# MSS_DEBUGSS register map
Vendor: Texas Instruments
Registers are 32-bit, read-write, no defined reset value unless marked. A register's access mark holds for its fields unless they carry their own. Offsets are as the file gives them; [hi:lo] are bit positions; {n}, {i} and the like mark numbered series; 'fields as' and 'values as' point back to an identical list.

## MSS_DEBUGSS (part 2 of 2)
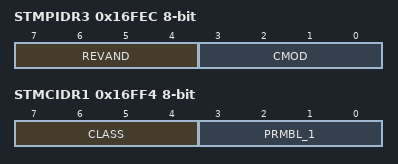
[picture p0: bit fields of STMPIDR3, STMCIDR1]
0x16FEC STMPIDR3 8-bit ro — Peripheral ID3
  [7:4] REVAND — Indicates minor errata fixes specific to the design, for example metal fixes after implementation. In most cases this field is zero. ARM recommends that the component designers ensure that the bit field can be changed by a metal fix if required, for example by driving the bit field from registers that reset to zero. 0x0 No metal fixes in the component.
  [3:0] CMOD — Where the component is reusable IP, this value indicates whether the customer has modified the behavior of the component. In most cases this field is zero. 0x0 No modifications made.
0x16FF0 STMCIDR0 8-bit ro — Component ID0
  [7:0] PRMBL_0 — Contains bits [31:21] of the component identification. 0x0D Identification value.
0x16FF4 STMCIDR1 8-bit ro — Component ID1
  [7:4] CLASS — Class of the component, for example, the ROM table or CoreSight component. 0x9 Indicates the component is a CoreSight component.
  [3:0] PRMBL_1 — Contains bits [19:16] of the component identification. 0x0 Identification value.
0x16FF8 STMCIDR2 8-bit ro — Component ID2
  [7:0] PRMBL_2 — Contains bits [15:8] of the component identification. 0x05 Identification value.
0x16FFC STMCIDR3 8-bit ro — Component ID3
  [7:0] PRMBL_3 — Contains bits [7:0] of the component identification. 0xB1 Identification value.
0x17000 MDO_TPIU_SPORTSZ ro — Supported port sizes
0x17004 MDO_TPIU_CPORTSZ — Current port size
0x17100 MDO_TPIU_STRIGM ro — Supported trigger modes
0x17104 MDO_TPIU_TRIGCNT — Trigger counter value
0x17108 MDO_TPIU_TRIGMUL — Trigger multiplier
0x17200 MDO_TPIU_STSTPTRN ro — Supported test pattern/modes
0x17204 MDO_TPIU_CTSTPTRN — Current test pattern/mode
0x17208 MDO_TPIU_TPRCNTR — Test pattern repeat counter
0x17300 MDO_TPIU_FFSTS ro — Formatter and flush status
0x17304 MDO_TPIU_FFCTRL — Formatter and flush control
0x17308 MDO_TPIU_FSCNTR — Formatter synchronization counter
0x17400 MDO_TPIU_EXCTLIN ro — EXTCTL In Port
0x17404 MDO_TPIU_EXCTLOUT — EXTCTL Out Port
0x17EE4 MDO_TPIU_ITTRFLINACK wo — Integration Register, ITTRFLINACK
0x17EE8 MDO_TPIU_ITTRFLIN ro — Integration Register, ITTRFLIN
0x17EEC MDO_TPIU_ITATBDATA0 ro — Integration Register, ITATBDATA0
0x17EF0 MDO_TPIU_ITATBCTR2 wo — Integration Register, ITATBCTR2
0x17EF4 MDO_TPIU_ITATBCTR1 ro — Integration Register, ITATBCTR1
0x17EF8 MDO_TPIU_ITATBCTR0 ro — Integration Register, ITATBCTR0
0x17F00 MDO_TPIU_ITCTRL — Integration Mode Control Register
0x17FA0 MDO_TPIU_CLAIMSET — Claim Tag Set
0x17FA4 MDO_TPIU_CLAIMCLR — Claim Tag Clear
0x17FB0 MDO_TPIU_LAR ro — Lock status
0x17FB4 MDO_TPIU_LSR wo — Lock Access
0x17FB8 MDO_TPIU_AUTHSTATUS ro — Authentication status
0x17FC8 MDO_TPIU_DEVID ro — Device ID
0x17FCC MDO_TPIU_DEVTYPE ro — Device type identifier
{0x17FC0+4i} MDO_TPIU_PIDR{i} ro (i=4..7) — Peripheral ID{i}
{0x17FE0+4i} MDO_TPIU_PIDR{i} ro (i=0..3) — Peripheral ID{i}
{0x17FF0+4i} MDO_TPIU_CIDR{i} ro (i=0..3) — Component ID{i}
0x18000 HSM_CM4_CTI_CONTROL — http://infocenter.arm.com/help/topic/com.arm.doc.ddi0314h/Chdjefbi.html http://infocenter.arm.com/help/topic/com.arm.doc.ddi0314h/Chdefejc.html
  [31:0] HSM_CM4_CTI_CONTROL — http://infocenter.arm.com/help/topic/com.arm.doc.ddi0480e/CHDGDIHE.html http://infocenter.arm.com/help/topic/com.arm.doc.ddi0480e/CHDHBDIA.html
0x18010 HSM_CM4_CTI_INTACK wo
0x18014 HSM_CM4_CTI_APPSET
0x18018 HSM_CM4_CTI_APPCLEAR wo
0x1801C HSM_CM4_CTI_APPPULSE wo
{0x18020+4i} HSM_CM4_CTI_INEN{i} (i=0..7)
{0x180A0+4i} HSM_CM4_CTI_OUTEN{i} (i=0..7)
0x18130 HSM_CM4_CTI_TRIGINSTATUS ro
0x18134 HSM_CM4_CTI_TRIGOUTSTATUS ro
0x18138 HSM_CM4_CTI_CHINSTATUS ro
0x1813C HSM_CM4_CTI_CHOUTSTATUS ro
0x18140 HSM_CM4_CTI_GATE
0x18144 HSM_CM4_CTI_ASICCTL
0x18EDC HSM_CM4_CTI_ITCHINACK wo
0x18EE0 HSM_CM4_CTI_ITTRIGINACK wo
0x18EE4 HSM_CM4_CTI_ITCHOUT wo
0x18EE8 HSM_CM4_CTI_ITTRIGOUT wo
0x18EEC HSM_CM4_CTI_ITCHOUTACK ro
0x18EF0 HSM_CM4_CTI_ITTRIGOUTACK ro
0x18EF4 HSM_CM4_CTI_ITCHIN ro
0x18EF8 HSM_CM4_CTI_ITTRIGIN ro
0x18F00 HSM_CM4_CTI_ITCTRL
0x18FA0 HSM_CM4_CTI_Claim_Tag_Set
0x18FA4 HSM_CM4_CTI_Claim_Tag_Clear
0x18FB0 HSM_CM4_CTI_Lock_Access_Register wo
0x18FB4 HSM_CM4_CTI_Lock_Status_Register ro
0x18FB8 HSM_CM4_CTI_Authentication_Status ro
0x18FC8 HSM_CM4_CTI_Device_ID ro
0x18FCC HSM_CM4_CTI_Device_Type_Identifier ro
{0x18FC0+4i} HSM_CM4_CTI_PeripheralID{i} ro (i=4..7)
{0x18FE0+4i} HSM_CM4_CTI_PeripheralID{i} ro (i=0..3)
{0x18FF0+4i} HSM_CM4_CTI_Component_ID{i} ro (i=0..3)
0x19000 DSS_CM4_CTI_CONTROL — http://infocenter.arm.com/help/topic/com.arm.doc.ddi0314h/Chdjefbi.html http://infocenter.arm.com/help/topic/com.arm.doc.ddi0314h/Chdefejc.html
0x19010 DSS_CM4_CTI_INTACK wo
0x19014 DSS_CM4_CTI_APPSET
0x19018 DSS_CM4_CTI_APPCLEAR wo
0x1901C DSS_CM4_CTI_APPPULSE wo
{0x19020+4i} DSS_CM4_CTI_INEN{i} (i=0..7)
{0x190A0+4i} DSS_CM4_CTI_OUTEN{i} (i=0..7)
0x19130 DSS_CM4_CTI_TRIGINSTATUS ro
0x19134 DSS_CM4_CTI_TRIGOUTSTATUS ro
0x19138 DSS_CM4_CTI_CHINSTATUS ro
0x1913C DSS_CM4_CTI_CHOUTSTATUS ro
0x19140 DSS_CM4_CTI_GATE
0x19144 DSS_CM4_CTI_ASICCTL
0x19EDC DSS_CM4_CTI_ITCHINACK wo
0x19EE0 DSS_CM4_CTI_ITTRIGINACK wo
0x19EE4 DSS_CM4_CTI_ITCHOUT wo
0x19EE8 DSS_CM4_CTI_ITTRIGOUT wo
0x19EEC DSS_CM4_CTI_ITCHOUTACK ro
0x19EF0 DSS_CM4_CTI_ITTRIGOUTACK ro
0x19EF4 DSS_CM4_CTI_ITCHIN ro
0x19EF8 DSS_CM4_CTI_ITTRIGIN ro
0x19F00 DSS_CM4_CTI_ITCTRL
0x19FA0 DSS_CM4_CTI_Claim_Tag_Set
0x19FA4 DSS_CM4_CTI_Claim_Tag_Clear
0x19FB0 DSS_CM4_CTI_Lock_Access_Register wo
0x19FB4 DSS_CM4_CTI_Lock_Status_Register ro
0x19FB8 DSS_CM4_CTI_Authentication_Status ro
0x19FC8 DSS_CM4_CTI_Device_ID ro
0x19FCC DSS_CM4_CTI_Device_Type_Identifier ro
{0x19FC0+4i} DSS_CM4_CTI_PeripheralID{i} ro (i=4..7)
{0x19FE0+4i} DSS_CM4_CTI_PeripheralID{i} ro (i=0..3)
{0x19FF0+4i} DSS_CM4_CTI_Component_ID{i} ro (i=0..3)
0x1A000 RSS_APB_DBGDIDR — Debug Identification Register
  [31:0] RSS_APB_DBGDIDR — http://infocenter.arm.com/help/topic/com.arm.doc.ddi0363e/Cegejeeb.html Debug Identification Register
0x1A018 RSS_APB_DBGWFAR — Watchpoint Fault Address Register
0x1A01C RSS_APB_DBGVCR — Vector Catch Register
0x1A024 RSS_APB_DBGECR — Not Implemented
0x1A028 RSS_APB_DBGDSCCR — Debug State Cache Control Register
0x1A080 RSS_APB_DBGDTRRX — Host to Target Data Transfer Register
0x1A084 RSS_APB_DBGITR — Instruction Transfer Register
0x1A088 RSS_APB_DBGDSCR — Debug Status and Control Register
0x1A08C RSS_APB_DBGDTRTX — Target to Host Data Transfer Register
0x1A090 RSS_APB_DBGDRCR — Debug Run Control Register
{0x1A100+4i} RSS_APB_DBGBVR{i} (i=0..7) — Break Point Value Register {i}
{0x1A140+4i} RSS_APB_DBGBCR{i} (i=0..7) — Break Point Control Register {i}
{0x1A180+4i} RSS_APB_DBGWVR{i} (i=0..7) — Watch Point Value Register {i}
{0x1A1C0+4i} RSS_APB_DBGWCR{i} (i=0..7) — Watch Point Control Register {i}
0x1A300 RSS_APB_DBGOSLAR — Not Implemented
0x1A304 RSS_APB_DBGOSLSR — Operating System Lock Status Register
0x1A308 RSS_APB_DBGOSSRR — Not Implemented
0x1A310 RSS_APB_DBGPRCR — Device Power Down and Reset Control Regsiter
0x1A314 RSS_APB_DBGPRSR — Device Power Down and Reset Status Register
0x1AD00 RSS_APB_PROCID_MIDR — Main ID Register
0x1AD04 RSS_APB_PROCID_CTR — Cache Type Register
0x1AD08 RSS_APB_PROCID_TCMTR — TCM Type Register
0x1AD10 RSS_APB_PROCID_MPUIR — MPU Type Register
0x1AD14 RSS_APB_PROCID_MPIDR — Multiprocessor Affinity Register
0x1AD20 RSS_APB_PROCID_PFR0 — Processor Feature Register 0
0x1AD24 RSS_APB_PROCID_PFR1 — Processor Feature Register 1
0x1AD28 RSS_APB_PROCID_DFR0 — Debug Feature Register 0
0x1AD2C RSS_APB_PROCID_AFR0 — Auxiliary Feature Register 0
0x1AD30 RSS_APB_PROCID_MMFR0 — Processor Feature Register 0
{0x1AD30+4i} RSS_APB_PROCID_MMFR{i} (i=1..3) — Memory Model Feature Register {i}
{0x1AD40+4i} RSS_APB_PROCID_ISAR{i} (i=0..5) — ISA Feature Register {i}
0x1AF00 RSS_APB_MR_ITCTRL — Integration Mode Control Registers
0x1AFA0 RSS_APB_MR_CLAIMSET — Claim Tag Set Register
0x1AFA4 RSS_APB_MR_CLAIMCLR — Claim Tag Clear Register
0x1AFB0 RSS_APB_MR_LOCKACCESS — Lock Access Register
0x1AFB4 RSS_APB_MR_LOCKSTATUS — Lock Status Register
0x1AFB8 RSS_APB_MR_AUTHSTATUS — Authentication Status Register
0x1AFC8 RSS_APB_MR_DEVID — Device Identifier
0x1AFCC RSS_APB_MR_DEVTYPE — Device Type Register
0x1AFD0 RSS_APB_PERIP_ID4
{0x1AFE0+4i} RSS_APB_PERIP_ID{i} (i=0..3)
{0x1AFF0+4i} RSS_APB_COMP_ID{i} (i=0..3)
0x30000 MSS_A_APB_DBGDIDR — Debug Identification Register
  [31:0] MSS_APB_DBGDIDR — http://infocenter.arm.com/help/topic/com.arm.doc.ddi0363e/Cegejeeb.html Debug Identification Register
0x30018 MSS_A_APB_DBGWFAR — Watchpoint Fault Address Register
  [31:0] MSS_APB_DBGWFAR
0x3001C MSS_A_APB_DBGVCR — Vector Catch Register
  [31:0] MSS_APB_DBGVCR
0x30024 MSS_A_APB_DBGECR — Not Implemented
  [31:0] MSS_APB_DBGECR
0x30028 MSS_A_APB_DBGDSCCR — Debug State Cache Control Register
  [31:0] MSS_APB_DBGDSCCR
0x30080 MSS_A_APB_DBGDTRRX — Host to Target Data Transfer Register
  [31:0] MSS_APB_DBGDTRRX
0x30084 MSS_A_APB_DBGITR — Instruction Transfer Register
  [31:0] MSS_APB_DBGITR
0x30088 MSS_A_APB_DBGDSCR — Debug Status and Control Register
  [31:0] MSS_APB_DBGDSCR
0x3008C MSS_A_APB_DBGDTRTX — Target to Host Data Transfer Register
  [31:0] MSS_APB_DBGDTRTX
0x30090 MSS_A_APB_DBGDRCR — Debug Run Control Register
  [31:0] MSS_APB_DBGDRCR
{0x30100+4i} MSS_A_APB_DBGBVR{i} (i=0..7) — Break Point Value Register {i}
  [31:0] MSS_APB_DBGBVR{i}
{0x30140+4i} MSS_A_APB_DBGBCR{i} (i=0..7) — Break Point Control Register {i}
  [31:0] MSS_APB_DBGBCR{i}
{0x30180+4i} MSS_A_APB_DBGWVR{i} (i=0..7) — Watch Point Value Register {i}
  [31:0] MSS_APB_DBGWVR{i}
{0x301C0+4i} MSS_A_APB_DBGWCR{i} (i=0..7) — Watch Point Control Register {i}
  [31:0] MSS_APB_DBGWCR{i}
0x30300 MSS_A_APB_DBGOSLAR — Not Implemented
  [31:0] MSS_APB_DBGOSLAR
0x30304 MSS_A_APB_DBGOSLSR — Operating System Lock Status Register
  [31:0] MSS_APB_DBGOSLSR
0x30308 MSS_A_APB_DBGOSSRR — Not Implemented
  [31:0] MSS_APB_DBGOSSRR
0x30310 MSS_A_APB_DBGPRCR — Device Power Down and Reset Control Regsiter
  [31:0] MSS_APB_DBGPRCR
0x30314 MSS_A_APB_DBGPRSR — Device Power Down and Reset Status Register
  [31:0] MSS_APB_DBGPRSR
0x30D00 MSS_A_APB_PROCID_MIDR — Main ID Register
  [31:0] MSS_APB_PROCID_MIDR
0x30D04 MSS_A_APB_PROCID_CTR — Cache Type Register
  [31:0] MSS_APB_PROCID_CTR
0x30D08 MSS_A_APB_PROCID_TCMTR — TCM Type Register
  [31:0] MSS_APB_PROCID_TCMTR
0x30D10 MSS_A_APB_PROCID_MPUIR — MPU Type Register
  [31:0] MSS_APB_PROCID_MPUIR
0x30D14 MSS_A_APB_PROCID_MPIDR — Multiprocessor Affinity Register
  [31:0] MSS_APB_PROCID_MPIDR
0x30D20 MSS_A_APB_PROCID_PFR0 — Processor Feature Register 0
  [31:0] MSS_APB_PROCID_PFR0
0x30D24 MSS_A_APB_PROCID_PFR1 — Processor Feature Register 1
  [31:0] MSS_APB_PROCID_PFR1
0x30D28 MSS_A_APB_PROCID_DFR0 — Debug Feature Register 0
  [31:0] MSS_APB_PROCID_DFR0
0x30D2C MSS_A_APB_PROCID_AFR0 — Auxiliary Feature Register 0
  [31:0] MSS_APB_PROCID_AFR0
0x30D30 MSS_A_APB_PROCID_MMFR0 — Processor Feature Register 0
  [31:0] MSS_APB_PROCID_MMFR0
{0x30D30+4i} MSS_A_APB_PROCID_MMFR{i} (i=1..3) — Memory Model Feature Register {i}
  [31:0] MSS_APB_PROCID_MMFR{i}
{0x30D40+4i} MSS_A_APB_PROCID_ISAR{i} (i=0..5) — ISA Feature Register {i}
  [31:0] MSS_APB_PROCID_ISAR{i}
0x30F00 MSS_A_APB_MR_ITCTRL — Integration Mode Control Registers
  [31:0] MSS_APB_MR_ITCTRL
0x30FA0 MSS_A_APB_MR_CLAIMSET — Claim Tag Set Register
  [31:0] MSS_APB_MR_CLAIMSET
0x30FA4 MSS_A_APB_MR_CLAIMCLR — Claim Tag Clear Register
  [31:0] MSS_APB_MR_CLAIMCLR
0x30FB0 MSS_A_APB_MR_LOCKACCESS — Lock Access Register
  [31:0] MSS_APB_MR_LOCKACCESS
0x30FB4 MSS_A_APB_MR_LOCKSTATUS — Lock Status Register
  [31:0] MSS_APB_MR_LOCKSTATUS
0x30FB8 MSS_A_APB_MR_AUTHSTATUS — Authentication Status Register
  [31:0] MSS_APB_MR_AUTHSTATUS
0x30FC8 MSS_A_APB_MR_DEVID — Device Identifier
  [31:0] MSS_APB_MR_DEVID
0x30FCC MSS_A_APB_MR_DEVTYPE — Device Type Register
  [31:0] MSS_APB_MR_DEVTYPE
0x30FD0 MSS_A_APB_PERIP_ID4
  [31:0] MSS_APB_PERIP_ID4
{0x30FE0+4i} MSS_A_APB_PERIP_ID{i} (i=0..3)
  [31:0] MSS_APB_PERIP_ID{i}
{0x30FF0+4i} MSS_A_APB_COMP_ID{i} (i=0..3)
  [31:0] MSS_APB_COMP_ID{i}
0x32000 MSS_B_APB_DBGDIDR — Debug Identification Register
  fields as MSS_A_APB_DBGDIDR
0x32018 MSS_B_APB_DBGWFAR — Watchpoint Fault Address Register
  [31:0] MSS_APB_DBGWFAR
0x3201C MSS_B_APB_DBGVCR — Vector Catch Register
  [31:0] MSS_APB_DBGVCR
0x32024 MSS_B_APB_DBGECR — Not Implemented
  [31:0] MSS_APB_DBGECR
0x32028 MSS_B_APB_DBGDSCCR — Debug State Cache Control Register
  [31:0] MSS_APB_DBGDSCCR
0x32080 MSS_B_APB_DBGDTRRX — Host to Target Data Transfer Register
  [31:0] MSS_APB_DBGDTRRX
0x32084 MSS_B_APB_DBGITR — Instruction Transfer Register
  [31:0] MSS_APB_DBGITR
0x32088 MSS_B_APB_DBGDSCR — Debug Status and Control Register
  [31:0] MSS_APB_DBGDSCR
0x3208C MSS_B_APB_DBGDTRTX — Target to Host Data Transfer Register
  [31:0] MSS_APB_DBGDTRTX
0x32090 MSS_B_APB_DBGDRCR — Debug Run Control Register
  [31:0] MSS_APB_DBGDRCR
{0x32100+4i} MSS_B_APB_DBGBVR{i} (i=0..7) — Break Point Value Register {i}
  [31:0] MSS_APB_DBGBVR{i}
{0x32140+4i} MSS_B_APB_DBGBCR{i} (i=0..7) — Break Point Control Register {i}
  [31:0] MSS_APB_DBGBCR{i}
{0x32180+4i} MSS_B_APB_DBGWVR{i} (i=0..7) — Watch Point Value Register {i}
  [31:0] MSS_APB_DBGWVR{i}
{0x321C0+4i} MSS_B_APB_DBGWCR{i} (i=0..7) — Watch Point Control Register {i}
  [31:0] MSS_APB_DBGWCR{i}
0x32300 MSS_B_APB_DBGOSLAR — Not Implemented
  [31:0] MSS_APB_DBGOSLAR
0x32304 MSS_B_APB_DBGOSLSR — Operating System Lock Status Register
  [31:0] MSS_APB_DBGOSLSR
0x32308 MSS_B_APB_DBGOSSRR — Not Implemented
  [31:0] MSS_APB_DBGOSSRR
0x32310 MSS_B_APB_DBGPRCR — Device Power Down and Reset Control Regsiter
  [31:0] MSS_APB_DBGPRCR
0x32314 MSS_B_APB_DBGPRSR — Device Power Down and Reset Status Register
  [31:0] MSS_APB_DBGPRSR
0x32D00 MSS_B_APB_PROCID_MIDR — Main ID Register
  [31:0] MSS_APB_PROCID_MIDR
0x32D04 MSS_B_APB_PROCID_CTR — Cache Type Register
  [31:0] MSS_APB_PROCID_CTR
0x32D08 MSS_B_APB_PROCID_TCMTR — TCM Type Register
  [31:0] MSS_APB_PROCID_TCMTR
0x32D10 MSS_B_APB_PROCID_MPUIR — MPU Type Register
  [31:0] MSS_APB_PROCID_MPUIR
0x32D14 MSS_B_APB_PROCID_MPIDR — Multiprocessor Affinity Register
  [31:0] MSS_APB_PROCID_MPIDR
0x32D20 MSS_B_APB_PROCID_PFR0 — Processor Feature Register 0
  [31:0] MSS_APB_PROCID_PFR0
0x32D24 MSS_B_APB_PROCID_PFR1 — Processor Feature Register 1
  [31:0] MSS_APB_PROCID_PFR1
0x32D28 MSS_B_APB_PROCID_DFR0 — Debug Feature Register 0
  [31:0] MSS_APB_PROCID_DFR0
0x32D2C MSS_B_APB_PROCID_AFR0 — Auxiliary Feature Register 0
  [31:0] MSS_APB_PROCID_AFR0
0x32D30 MSS_B_APB_PROCID_MMFR0 — Processor Feature Register 0
  [31:0] MSS_APB_PROCID_MMFR0
{0x32D30+4i} MSS_B_APB_PROCID_MMFR{i} (i=1..3) — Memory Model Feature Register {i}
  [31:0] MSS_APB_PROCID_MMFR{i}
{0x32D40+4i} MSS_B_APB_PROCID_ISAR{i} (i=0..5) — ISA Feature Register {i}
  [31:0] MSS_APB_PROCID_ISAR{i}
0x32F00 MSS_B_APB_MR_ITCTRL — Integration Mode Control Registers
  [31:0] MSS_APB_MR_ITCTRL
0x32FA0 MSS_B_APB_MR_CLAIMSET — Claim Tag Set Register
  [31:0] MSS_APB_MR_CLAIMSET
0x32FA4 MSS_B_APB_MR_CLAIMCLR — Claim Tag Clear Register
  [31:0] MSS_APB_MR_CLAIMCLR
0x32FB0 MSS_B_APB_MR_LOCKACCESS — Lock Access Register
  [31:0] MSS_APB_MR_LOCKACCESS
0x32FB4 MSS_B_APB_MR_LOCKSTATUS — Lock Status Register
  [31:0] MSS_APB_MR_LOCKSTATUS
0x32FB8 MSS_B_APB_MR_AUTHSTATUS — Authentication Status Register
  [31:0] MSS_APB_MR_AUTHSTATUS
0x32FC8 MSS_B_APB_MR_DEVID — Device Identifier
  [31:0] MSS_APB_MR_DEVID
0x32FCC MSS_B_APB_MR_DEVTYPE — Device Type Register
  [31:0] MSS_APB_MR_DEVTYPE
0x32FD0 MSS_B_APB_PERIP_ID4
  [31:0] MSS_APB_PERIP_ID4
{0x32FE0+4i} MSS_B_APB_PERIP_ID{i} (i=0..3)
  [31:0] MSS_APB_PERIP_ID{i}
{0x32FF0+4i} MSS_B_APB_COMP_ID{i} (i=0..3)
  [31:0] MSS_APB_COMP_ID{i}
0x38000 MSS_A_CTI_CONTROL — http://infocenter.arm.com/help/topic/com.arm.doc.ddi0314h/Chdjefbi.html http://infocenter.arm.com/help/topic/com.arm.doc.ddi0314h/Chdefejc.html
  [31:0] MSS_CTI_CONTROL — http://infocenter.arm.com/help/topic/com.arm.doc.ddi0480e/CHDGDIHE.html http://infocenter.arm.com/help/topic/com.arm.doc.ddi0480e/CHDHBDIA.html
0x38010 MSS_A_CTI_INTACK wo
  [31:0] MSS_CTI_INTACK
0x38014 MSS_A_CTI_APPSET
  [31:0] MSS_CTI_APPSET
0x38018 MSS_A_CTI_APPCLEAR wo
  [31:0] MSS_CTI_APPCLEAR
0x3801C MSS_A_CTI_APPPULSE wo
  [31:0] MSS_CTI_APPPULSE
{0x38020+4i} MSS_A_CTI_INEN{i} (i=0..7)
  [31:0] MSS_CTI_INEN{i}
{0x380A0+4i} MSS_A_CTI_OUTEN{i} (i=0..7)
  [31:0] MSS_CTI_OUTEN{i}
0x38130 MSS_A_CTI_TRIGINSTATUS ro
  [31:0] MSS_CTI_TRIGINSTATUS
0x38134 MSS_A_CTI_TRIGOUTSTATUS ro
  [31:0] MSS_CTI_TRIGOUTSTATUS
0x38138 MSS_A_CTI_CHINSTATUS ro
  [31:0] MSS_CTI_CHINSTATUS
0x3813C MSS_A_CTI_CHOUTSTATUS ro
  [31:0] MSS_CTI_CHOUTSTATUS
0x38140 MSS_A_CTI_GATE
  [31:0] MSS_CTI_GATE
0x38144 MSS_A_CTI_ASICCTL
  [31:0] MSS_CTI_ASICCTL
0x38EDC MSS_A_CTI_ITCHINACK wo
  [31:0] MSS_CTI_ITCHINACK
0x38EE0 MSS_A_CTI_ITTRIGINACK wo
  [31:0] MSS_CTI_ITTRIGINACK
0x38EE4 MSS_A_CTI_ITCHOUT wo
  [31:0] MSS_CTI_ITCHOUT
0x38EE8 MSS_A_CTI_ITTRIGOUT wo
  [31:0] MSS_CTI_ITTRIGOUT
0x38EEC MSS_A_CTI_ITCHOUTACK ro
  [31:0] MSS_CTI_ITCHOUTACK
0x38EF0 MSS_A_CTI_ITTRIGOUTACK ro
  [31:0] MSS_CTI_ITTRIGOUTACK
0x38EF4 MSS_A_CTI_ITCHIN ro
  [31:0] MSS_CTI_ITCHIN
0x38EF8 MSS_A_CTI_ITTRIGIN ro
  [31:0] MSS_CTI_ITTRIGIN
0x38F00 MSS_A_CTI_ITCTRL
  [31:0] MSS_CTI_ITCTRL
0x38FA0 MSS_A_CTI_Claim_Tag_Set
  [31:0] MSS_CTI_Claim_Tag_Set
0x38FA4 MSS_A_CTI_Claim_Tag_Clear
  [31:0] MSS_CTI_Claim_Tag_Clear
0x38FB0 MSS_A_CTI_Lock_Access_Register wo
  [31:0] MSS_CTI_Lock_Access_Register
0x38FB4 MSS_A_CTI_Lock_Status_Register ro
  [31:0] MSS_CTI_Lock_Status_Register
0x38FB8 MSS_A_CTI_Authentication_Status ro
  [31:0] MSS_CTI_Authentication_Status
0x38FC8 MSS_A_CTI_Device_ID ro
  [31:0] MSS_CTI_Device_ID
0x38FCC MSS_A_CTI_Device_Type_Identifier ro
  [31:0] MSS_CTI_Device_Type_Identifier
{0x38FC0+4i} MSS_A_CTI_PeripheralID{i} ro (i=4..7)
  [31:0] MSS_CTI_PeripheralID{i}
{0x38FE0+4i} MSS_A_CTI_PeripheralID{i} ro (i=0..3)
  [31:0] MSS_CTI_PeripheralID{i}
{0x38FF0+4i} MSS_A_CTI_Component_ID{i} ro (i=0..3)
  [31:0] MSS_CTI_Component_ID{i}
0x39000 MSS_B_CTI_CONTROL — http://infocenter.arm.com/help/topic/com.arm.doc.ddi0314h/Chdjefbi.html http://infocenter.arm.com/help/topic/com.arm.doc.ddi0314h/Chdefejc.html
  fields as MSS_A_CTI_CONTROL
0x39010 MSS_B_CTI_INTACK wo
  [31:0] MSS_CTI_INTACK
0x39014 MSS_B_CTI_APPSET
  [31:0] MSS_CTI_APPSET
0x39018 MSS_B_CTI_APPCLEAR wo
  [31:0] MSS_CTI_APPCLEAR
0x3901C MSS_B_CTI_APPPULSE wo
  [31:0] MSS_CTI_APPPULSE
{0x39020+4i} MSS_B_CTI_INEN{i} (i=0..7)
  [31:0] MSS_CTI_INEN{i}
{0x390A0+4i} MSS_B_CTI_OUTEN{i} (i=0..7)
  [31:0] MSS_CTI_OUTEN{i}
0x39130 MSS_B_CTI_TRIGINSTATUS ro
  [31:0] MSS_CTI_TRIGINSTATUS
0x39134 MSS_B_CTI_TRIGOUTSTATUS ro
  [31:0] MSS_CTI_TRIGOUTSTATUS
0x39138 MSS_B_CTI_CHINSTATUS ro
  [31:0] MSS_CTI_CHINSTATUS
0x3913C MSS_B_CTI_CHOUTSTATUS ro
  [31:0] MSS_CTI_CHOUTSTATUS
0x39140 MSS_B_CTI_GATE
  [31:0] MSS_CTI_GATE
0x39144 MSS_B_CTI_ASICCTL
  [31:0] MSS_CTI_ASICCTL
0x39EDC MSS_B_CTI_ITCHINACK wo
  [31:0] MSS_CTI_ITCHINACK
0x39EE0 MSS_B_CTI_ITTRIGINACK wo
  [31:0] MSS_CTI_ITTRIGINACK
0x39EE4 MSS_B_CTI_ITCHOUT wo
  [31:0] MSS_CTI_ITCHOUT
0x39EE8 MSS_B_CTI_ITTRIGOUT wo
  [31:0] MSS_CTI_ITTRIGOUT
0x39EEC MSS_B_CTI_ITCHOUTACK ro
  [31:0] MSS_CTI_ITCHOUTACK
0x39EF0 MSS_B_CTI_ITTRIGOUTACK ro
  [31:0] MSS_CTI_ITTRIGOUTACK
0x39EF4 MSS_B_CTI_ITCHIN ro
  [31:0] MSS_CTI_ITCHIN
0x39EF8 MSS_B_CTI_ITTRIGIN ro
  [31:0] MSS_CTI_ITTRIGIN
0x39F00 MSS_B_CTI_ITCTRL
  [31:0] MSS_CTI_ITCTRL
0x39FA0 MSS_B_CTI_Claim_Tag_Set
  [31:0] MSS_CTI_Claim_Tag_Set
0x39FA4 MSS_B_CTI_Claim_Tag_Clear
  [31:0] MSS_CTI_Claim_Tag_Clear
0x39FB0 MSS_B_CTI_Lock_Access_Register wo
  [31:0] MSS_CTI_Lock_Access_Register
0x39FB4 MSS_B_CTI_Lock_Status_Register ro
  [31:0] MSS_CTI_Lock_Status_Register
0x39FB8 MSS_B_CTI_Authentication_Status ro
  [31:0] MSS_CTI_Authentication_Status
0x39FC8 MSS_B_CTI_Device_ID ro
  [31:0] MSS_CTI_Device_ID
0x39FCC MSS_B_CTI_Device_Type_Identifier ro
  [31:0] MSS_CTI_Device_Type_Identifier
{0x39FC0+4i} MSS_B_CTI_PeripheralID{i} ro (i=4..7)
  [31:0] MSS_CTI_PeripheralID{i}
{0x39FE0+4i} MSS_B_CTI_PeripheralID{i} ro (i=0..3)
  [31:0] MSS_CTI_PeripheralID{i}
{0x39FF0+4i} MSS_B_CTI_Component_ID{i} ro (i=0..3)
  [31:0] MSS_CTI_Component_ID{i}
0x3C000 MSS_A_ETM_CR
  [31:0] MSS_ETM_CR — http://infocenter.arm.com/help/index.jsp?topic=/com.arm.doc.ihi0014q/Chdfiagc.html http://infocenter.arm.com/help/topic/com.arm.doc.ihi0014q/I84249.html
0x3C004 MSS_A_ETM_CCR ro
  [31:0] MSS_ETM_CCR
0x3C008 MSS_A_ETM_TRIGGER
  [31:0] MSS_ETM_TRIGGER
0x3C00C MSS_A_ETM_ASICCTLR
  [31:0] MSS_ETM_ASICCTLR
0x3C010 MSS_A_ETM_SR
  [31:0] MSS_ETM_SR
0x3C014 MSS_A_ETM_SCR ro
  [31:0] MSS_ETM_SCR
0x3C018 MSS_A_ETM_TSSCR
  [31:0] MSS_ETM_TSSCR
0x3C01C MSS_A_ETM_TECR2
  [31:0] MSS_ETM_TECR2
0x3C020 MSS_A_ETM_TEEVR
  [31:0] MSS_ETM_TEEVR
0x3C024 MSS_A_ETM_TECR1
  [31:0] MSS_ETM_TECR1
0x3C028 MSS_A_ETM_FFRR
  [31:0] MSS_ETM_FFRR
0x3C02C MSS_A_ETM_FFLR
  [31:0] MSS_ETM_FFLR
0x3C030 MSS_A_ETM_VDEVR
  [31:0] MSS_ETM_VDEVR
{0x3C030+4i} MSS_A_ETM_VDCR{i} (i=1..3)
  [31:0] MSS_ETM_VDCR{i}
{0x3C03C+4i} MSS_A_ETM_ACVR{i} (i=1..16)
  [31:0] MSS_ETM_ACVR{i}
{0x3C07C+4i} MSS_A_ETM_ACTR{i} (i=1..16)
  [31:0] MSS_ETM_ACTR{i}
{0x3C0B8+8i} MSS_A_ETM_DCVR{i} (i=1..8)
  [31:0] MSS_ETM_DCVR{i}
{0x3C0F8+8i} MSS_A_ETM_DCMR{i} (i=1..8)
  [31:0] MSS_ETM_DCMR{i}
{0x3C13C+4i} MSS_A_ETM_CNTRLDVR{i} (i=1..4)
  [31:0] MSS_ETM_CNTRLDVR{i}
{0x3C14C+4i} MSS_A_ETM_CNTENR{i} (i=1..4)
  [31:0] MSS_ETM_CNTENR{i}
{0x3C15C+4i} MSS_A_ETM_CNTRLDEVR{i} (i=1..4)
  [31:0] MSS_ETM_CNTRLDEVR{i}
{0x3C16C+4i} MSS_A_ETM_CNTVR{i} (i=1..4)
  [31:0] MSS_ETM_CNTVR{i}
0x3C180 MSS_A_ETM_SQ12EVR
  [31:0] MSS_ETM_SQ12EVR
0x3C184 MSS_A_ETM_SQ21EVR
  [31:0] MSS_ETM_SQ21EVR
0x3C188 MSS_A_ETM_SQ23EVR
  [31:0] MSS_ETM_SQ23EVR
0x3C18C MSS_A_ETM_SQ31EVR
  [31:0] MSS_ETM_SQ31EVR
0x3C190 MSS_A_ETM_SQ32EVR
  [31:0] MSS_ETM_SQ32EVR
0x3C194 MSS_A_ETM_SQ13EVR
  [31:0] MSS_ETM_SQ13EVR
0x3C19C MSS_A_ETM_SQR
  [31:0] MSS_ETM_SQR
{0x3C19C+4i} MSS_A_ETM_EXTOUTEVR{i} (i=1..4)
  [31:0] MSS_ETM_EXTOUTEVR{i}
{0x3C1AC+4i} MSS_A_ETM_CIDCVR{i} (i=1..3)
  [31:0] MSS_ETM_CIDCVR{i}
0x3C1BC MSS_A_ETM_CIDCMR
  [31:0] MSS_ETM_CIDCMR
0x3C1E0 MSS_A_ETM_SYNCFR
  [31:0] MSS_ETM_SYNCFR
0x3C1E4 MSS_A_ETM_IDR ro
  [31:0] MSS_ETM_IDR
0x3C1E8 MSS_A_ETM_CCER ro
  [31:0] MSS_ETM_CCER
0x3C1EC MSS_A_ETM_EXTINSELR
  [31:0] MSS_ETM_EXTINSELR
0x3C200 MSS_A_ETM_TRACEIDR
  [31:0] MSS_ETM_TRACEIDR
0x3C314 MSS_A_ETM_PDSR ro
  [31:0] MSS_ETM_PDSR
0x3CED8 MSS_A_ETM_ITETMIF ro
  [31:0] MSS_ETM_ITETMIF
0x3CEDC MSS_A_ETM_ITMISCOUT wo
  [31:0] MSS_ETM_ITMISCOUT
0x3CEE0 MSS_A_ETM_ITMISCIN ro
  [31:0] MSS_ETM_ITMISCIN
0x3CEE4 MSS_A_ETM_ITTRIGGERACK ro
  [31:0] MSS_ETM_ITTRIGGERACK
0x3CEE8 MSS_A_ETM_ITTRIGGERREQ wo
  [31:0] MSS_ETM_ITTRIGGERREQ
0x3CEEC MSS_A_ETM_ITATBDATA0 wo
  [31:0] MSS_ETM_ITATBDATA0
0x3CEF0 MSS_A_ETM_ITATBCTR2 ro
  [31:0] MSS_ETM_ITATBCTR2
0x3CEF4 MSS_A_ETM_ITATBCTR1 wo
  [31:0] MSS_ETM_ITATBCTR1
0x3CEF8 MSS_A_ETM_ITATBCTR0 wo
  [31:0] MSS_ETM_ITATBCTR0
0x3CF00 MSS_A_ETM_ITCTRL
  [31:0] MSS_ETM_ITCTRL
0x3CFA0 MSS_A_ETM_CLAIMSET
  [31:0] MSS_ETM_CLAIMSET
0x3CFA4 MSS_A_ETM_CLAIMCLR
  [31:0] MSS_ETM_CLAIMCLR
0x3CFB0 MSS_A_ETM_LAR wo
  [31:0] MSS_ETM_LAR
0x3CFB4 MSS_A_ETM_LSR ro
  [31:0] MSS_ETM_LSR
0x3CFB8 MSS_A_ETM_AUTHSTATUS ro
  [31:0] MSS_ETM_AUTHSTATUS
0x3CFC8 MSS_A_ETM_DEVID ro
  [31:0] MSS_ETM_DEVID
0x3CFCC MSS_A_ETM_DEVTYPE ro
  [31:0] MSS_ETM_DEVTYPE
{0x3CFC0+4i} MSS_A_ETM_PIDR{i} ro (i=4..7)
  [31:0] MSS_ETM_PIDR{i}
{0x3CFE0+4i} MSS_A_ETM_PIDR{i} ro (i=0..3)
  [31:0] MSS_ETM_PIDR{i}
{0x3CFF0+4i} MSS_A_ETM_CIDR{i} ro (i=0..3)
  [31:0] MSS_ETM_CIDR{i}
0x3D000 MSS_B_ETM_CR
  fields as MSS_A_ETM_CR
0x3D004 MSS_B_ETM_CCR ro
  [31:0] MSS_ETM_CCR
0x3D008 MSS_B_ETM_TRIGGER
  [31:0] MSS_ETM_TRIGGER
0x3D00C MSS_B_ETM_ASICCTLR
  [31:0] MSS_ETM_ASICCTLR
0x3D010 MSS_B_ETM_SR
  [31:0] MSS_ETM_SR
0x3D014 MSS_B_ETM_SCR ro
  [31:0] MSS_ETM_SCR
0x3D018 MSS_B_ETM_TSSCR
  [31:0] MSS_ETM_TSSCR
0x3D01C MSS_B_ETM_TECR2
  [31:0] MSS_ETM_TECR2
0x3D020 MSS_B_ETM_TEEVR
  [31:0] MSS_ETM_TEEVR
0x3D024 MSS_B_ETM_TECR1
  [31:0] MSS_ETM_TECR1
0x3D028 MSS_B_ETM_FFRR
  [31:0] MSS_ETM_FFRR
0x3D02C MSS_B_ETM_FFLR
  [31:0] MSS_ETM_FFLR
0x3D030 MSS_B_ETM_VDEVR
  [31:0] MSS_ETM_VDEVR
{0x3D030+4i} MSS_B_ETM_VDCR{i} (i=1..3)
  [31:0] MSS_ETM_VDCR{i}
{0x3D03C+4i} MSS_B_ETM_ACVR{i} (i=1..16)
  [31:0] MSS_ETM_ACVR{i}
{0x3D07C+4i} MSS_B_ETM_ACTR{i} (i=1..16)
  [31:0] MSS_ETM_ACTR{i}
{0x3D0B8+8i} MSS_B_ETM_DCVR{i} (i=1..8)
  [31:0] MSS_ETM_DCVR{i}
{0x3D0F8+8i} MSS_B_ETM_DCMR{i} (i=1..8)
  [31:0] MSS_ETM_DCMR{i}
{0x3D13C+4i} MSS_B_ETM_CNTRLDVR{i} (i=1..4)
  [31:0] MSS_ETM_CNTRLDVR{i}
{0x3D14C+4i} MSS_B_ETM_CNTENR{i} (i=1..4)
  [31:0] MSS_ETM_CNTENR{i}
{0x3D15C+4i} MSS_B_ETM_CNTRLDEVR{i} (i=1..4)
  [31:0] MSS_ETM_CNTRLDEVR{i}
{0x3D16C+4i} MSS_B_ETM_CNTVR{i} (i=1..4)
  [31:0] MSS_ETM_CNTVR{i}
0x3D180 MSS_B_ETM_SQ12EVR
  [31:0] MSS_ETM_SQ12EVR
0x3D184 MSS_B_ETM_SQ21EVR
  [31:0] MSS_ETM_SQ21EVR
0x3D188 MSS_B_ETM_SQ23EVR
  [31:0] MSS_ETM_SQ23EVR
0x3D18C MSS_B_ETM_SQ31EVR
  [31:0] MSS_ETM_SQ31EVR
0x3D190 MSS_B_ETM_SQ32EVR
  [31:0] MSS_ETM_SQ32EVR
0x3D194 MSS_B_ETM_SQ13EVR
  [31:0] MSS_ETM_SQ13EVR
0x3D19C MSS_B_ETM_SQR
  [31:0] MSS_ETM_SQR
{0x3D19C+4i} MSS_B_ETM_EXTOUTEVR{i} (i=1..4)
  [31:0] MSS_ETM_EXTOUTEVR{i}
{0x3D1AC+4i} MSS_B_ETM_CIDCVR{i} (i=1..3)
  [31:0] MSS_ETM_CIDCVR{i}
0x3D1BC MSS_B_ETM_CIDCMR
  [31:0] MSS_ETM_CIDCMR
0x3D1E0 MSS_B_ETM_SYNCFR
  [31:0] MSS_ETM_SYNCFR
0x3D1E4 MSS_B_ETM_IDR ro
  [31:0] MSS_ETM_IDR
0x3D1E8 MSS_B_ETM_CCER ro
  [31:0] MSS_ETM_CCER
0x3D1EC MSS_B_ETM_EXTINSELR
  [31:0] MSS_ETM_EXTINSELR
0x3D200 MSS_B_ETM_TRACEIDR
  [31:0] MSS_ETM_TRACEIDR
0x3D314 MSS_B_ETM_PDSR ro
  [31:0] MSS_ETM_PDSR
0x3DED8 MSS_B_ETM_ITETMIF ro
  [31:0] MSS_ETM_ITETMIF
0x3DEDC MSS_B_ETM_ITMISCOUT wo
  [31:0] MSS_ETM_ITMISCOUT
0x3DEE0 MSS_B_ETM_ITMISCIN ro
  [31:0] MSS_ETM_ITMISCIN
0x3DEE4 MSS_B_ETM_ITTRIGGERACK ro
  [31:0] MSS_ETM_ITTRIGGERACK
0x3DEE8 MSS_B_ETM_ITTRIGGERREQ wo
  [31:0] MSS_ETM_ITTRIGGERREQ
0x3DEEC MSS_B_ETM_ITATBDATA0 wo
  [31:0] MSS_ETM_ITATBDATA0
0x3DEF0 MSS_B_ETM_ITATBCTR2 ro
  [31:0] MSS_ETM_ITATBCTR2
0x3DEF4 MSS_B_ETM_ITATBCTR1 wo
  [31:0] MSS_ETM_ITATBCTR1
0x3DEF8 MSS_B_ETM_ITATBCTR0 wo
  [31:0] MSS_ETM_ITATBCTR0
0x3DF00 MSS_B_ETM_ITCTRL
  [31:0] MSS_ETM_ITCTRL
0x3DFA0 MSS_B_ETM_CLAIMSET
  [31:0] MSS_ETM_CLAIMSET
0x3DFA4 MSS_B_ETM_CLAIMCLR
  [31:0] MSS_ETM_CLAIMCLR
0x3DFB0 MSS_B_ETM_LAR wo
  [31:0] MSS_ETM_LAR
0x3DFB4 MSS_B_ETM_LSR ro
  [31:0] MSS_ETM_LSR
0x3DFB8 MSS_B_ETM_AUTHSTATUS ro
  [31:0] MSS_ETM_AUTHSTATUS
0x3DFC8 MSS_B_ETM_DEVID ro
  [31:0] MSS_ETM_DEVID
0x3DFCC MSS_B_ETM_DEVTYPE ro
  [31:0] MSS_ETM_DEVTYPE
{0x3DFC0+4i} MSS_B_ETM_PIDR{i} ro (i=4..7)
  [31:0] MSS_ETM_PIDR{i}
{0x3DFE0+4i} MSS_B_ETM_PIDR{i} ro (i=0..3)
  [31:0] MSS_ETM_PIDR{i}
{0x3DFF0+4i} MSS_B_ETM_CIDR{i} ro (i=0..3)
  [31:0] MSS_ETM_CIDR{i}
